AUTOSAR XML (schema 4-2-1)
standard types defined: boolean, float32, uint8, boolean_CompuMethod, boolean_DataConstr, float32_DataConstr, uint8_DataConstr
package /ComponentTypes
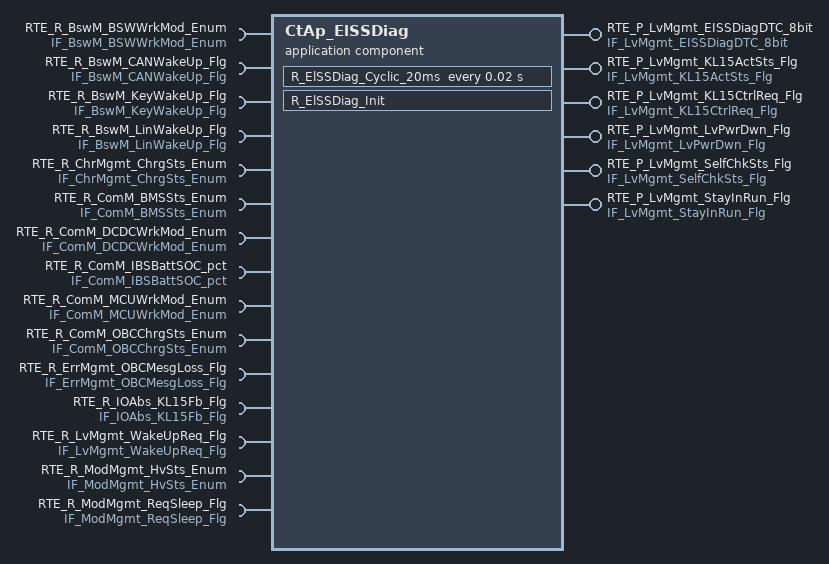
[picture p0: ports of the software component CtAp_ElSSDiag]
  application sw component type CtAp_ElSSDiag
    6 x provide port:
      RTE_P_LvMgmt_EISSDiagDTC_8bit: nonqueued-sender-com-spec{data-element=tec_LvMgmt_EISSDiagDTC_8bit, init-value=0}, provided-interface=IF_LvMgmt_EISSDiagDTC_8bit
      RTE_P_LvMgmt_KL15ActSts_Flg: nonqueued-sender-com-spec{data-element=tec_LvMgmt_KL15ActSts_Flg, init-value=0}, provided-interface=IF_LvMgmt_KL15ActSts_Flg
      RTE_P_LvMgmt_KL15CtrlReq_Flg: nonqueued-sender-com-spec{data-element=tec_LvMgmt_KL15CtrlReq_Flg, init-value=0}, provided-interface=IF_LvMgmt_KL15CtrlReq_Flg
      RTE_P_LvMgmt_LvPwrDwn_Flg: nonqueued-sender-com-spec{data-element=tec_LvMgmt_LvPwrDwn_Flg, init-value=0}, provided-interface=IF_LvMgmt_LvPwrDwn_Flg
      RTE_P_LvMgmt_SelfChkSts_Flg: nonqueued-sender-com-spec{data-element=tec_LvMgmt_SelfChkSts_Flg, init-value=0}, provided-interface=IF_LvMgmt_SelfChkSts_Flg
      RTE_P_LvMgmt_StayInRun_Flg: nonqueued-sender-com-spec{data-element=tec_LvMgmt_StayInRun_Flg, init-value=0}, provided-interface=IF_LvMgmt_StayInRun_Flg
    15 x require port:
      RTE_R_BswM_BSWWrkMod_Enum: nonqueued-receiver-com-spec{data-element=tec_BswM_BSWWrkMod_Enum, filter=data-filter-type=ALWAYS, init-value=0}, required-interface=IF_BswM_BSWWrkMod_Enum
      RTE_R_BswM_CANWakeUp_Flg: nonqueued-receiver-com-spec{data-element=tec_BswM_CANWakeUp_Flg, filter=data-filter-type=ALWAYS, init-value=0}, required-interface=IF_BswM_CANWakeUp_Flg
      RTE_R_BswM_KeyWakeUp_Flg: nonqueued-receiver-com-spec{data-element=tec_BswM_KeyWakeUp_Flg, filter=data-filter-type=ALWAYS, init-value=0}, required-interface=IF_BswM_KeyWakeUp_Flg
      RTE_R_BswM_LinWakeUp_Flg: nonqueued-receiver-com-spec{data-element=tec_BswM_LinWakeUp_Flg, filter=data-filter-type=ALWAYS, init-value=0}, required-interface=IF_BswM_LinWakeUp_Flg
      RTE_R_ChrMgmt_ChrgSts_Enum: nonqueued-receiver-com-spec{data-element=tec_ChrMgmt_ChrgSts_Enum, filter=data-filter-type=ALWAYS, init-value=0}, required-interface=IF_ChrMgmt_ChrgSts_Enum
      RTE_R_ComM_BMSSts_Enum: nonqueued-receiver-com-spec{data-element=tec_ComM_BMSSts_Enum, filter=data-filter-type=ALWAYS, init-value=0}, required-interface=IF_ComM_BMSSts_Enum
      RTE_R_ComM_DCDCWrkMod_Enum: nonqueued-receiver-com-spec{data-element=tec_ComM_DCDCWrkMod_Enum, filter=data-filter-type=ALWAYS, init-value=0}, required-interface=IF_ComM_DCDCWrkMod_Enum
      RTE_R_ComM_IBSBattSOC_pct: nonqueued-receiver-com-spec{data-element=tec_ComM_IBSBattSOC_pct, filter=data-filter-type=ALWAYS, init-value=0}, required-interface=IF_ComM_IBSBattSOC_pct
      RTE_R_ComM_MCUWrkMod_Enum: nonqueued-receiver-com-spec{data-element=tec_ComM_MCUWrkMod_Enum, filter=data-filter-type=ALWAYS, init-value=0}, required-interface=IF_ComM_MCUWrkMod_Enum
      RTE_R_ComM_OBCChrgSts_Enum: nonqueued-receiver-com-spec{data-element=tec_ComM_OBCChrgSts_Enum, filter=data-filter-type=ALWAYS, init-value=0}, required-interface=IF_ComM_OBCChrgSts_Enum
      RTE_R_ErrMgmt_OBCMesgLoss_Flg: nonqueued-receiver-com-spec{data-element=tec_ErrMgmt_OBCMesgLoss_Flg, filter=data-filter-type=ALWAYS, init-value=0}, required-interface=IF_ErrMgmt_OBCMesgLoss_Flg
      RTE_R_IOAbs_KL15Fb_Flg: nonqueued-receiver-com-spec{data-element=tec_IOAbs_KL15Fb_Flg, filter=data-filter-type=ALWAYS, init-value=0}, required-interface=IF_IOAbs_KL15Fb_Flg
      RTE_R_LvMgmt_WakeUpReq_Flg: nonqueued-receiver-com-spec{data-element=tec_LvMgmt_WakeUpReq_Flg, filter=data-filter-type=ALWAYS, init-value=0}, required-interface=IF_LvMgmt_WakeUpReq_Flg
      RTE_R_ModMgmt_HvSts_Enum: nonqueued-receiver-com-spec{data-element=tec_ModMgmt_HvSts_Enum, filter=data-filter-type=ALWAYS, init-value=0}, required-interface=IF_ModMgmt_HvSts_Enum
      RTE_R_ModMgmt_ReqSleep_Flg: nonqueued-receiver-com-spec{data-element=tec_ModMgmt_ReqSleep_Flg, filter=data-filter-type=ALWAYS, init-value=0}, required-interface=IF_ModMgmt_ReqSleep_Flg
    behavior CtAp_ElSSDiag_InternalBehavior
      timing event TMT_R_ElSSDiag_Cyclic_20ms: start-on-event=R_ElSSDiag_Cyclic_20ms, period=0.02
      init event CtAp_ElSSDiag_InitEvent: start-on-event=R_ElSSDiag_Init
      runnable R_ElSSDiag_Cyclic_20ms
        data-receive-point-by-arguments:
          15 x access:
            REC_RTE_R_BswM_BSWWrkMod_Enum_tec_BswM_BSWWrkMod_Enum: accessed-variable=RTE_R_BswM_BSWWrkMod_Enum.tec_BswM_BSWWrkMod_Enum
            REC_RTE_R_BswM_CANWakeUp_Flg_tec_BswM_CANWakeUp_Flg: accessed-variable=RTE_R_BswM_CANWakeUp_Flg.tec_BswM_CANWakeUp_Flg
            REC_RTE_R_BswM_KeyWakeUp_Flg_tec_BswM_KeyWakeUp_Flg: accessed-variable=RTE_R_BswM_KeyWakeUp_Flg.tec_BswM_KeyWakeUp_Flg
            REC_RTE_R_BswM_LinWakeUp_Flg_tec_BswM_LinWakeUp_Flg: accessed-variable=RTE_R_BswM_LinWakeUp_Flg.tec_BswM_LinWakeUp_Flg
            REC_RTE_R_ChrMgmt_ChrgSts_Enum_tec_ChrMgmt_ChrgSts_Enum: accessed-variable=RTE_R_ChrMgmt_ChrgSts_Enum.tec_ChrMgmt_ChrgSts_Enum
            REC_RTE_R_ComM_BMSSts_Enum_tec_ComM_BMSSts_Enum: accessed-variable=RTE_R_ComM_BMSSts_Enum.tec_ComM_BMSSts_Enum
            REC_RTE_R_ComM_DCDCWrkMod_Enum_tec_ComM_DCDCWrkMod_Enum: accessed-variable=RTE_R_ComM_DCDCWrkMod_Enum.tec_ComM_DCDCWrkMod_Enum
            REC_RTE_R_ComM_IBSBattSOC_pct_tec_ComM_IBSBattSOC_pct: accessed-variable=RTE_R_ComM_IBSBattSOC_pct.tec_ComM_IBSBattSOC_pct
            REC_RTE_R_ComM_MCUWrkMod_Enum_tec_ComM_MCUWrkMod_Enum: accessed-variable=RTE_R_ComM_MCUWrkMod_Enum.tec_ComM_MCUWrkMod_Enum
            REC_RTE_R_ComM_OBCChrgSts_Enum_tec_ComM_OBCChrgSts_Enum: accessed-variable=RTE_R_ComM_OBCChrgSts_Enum.tec_ComM_OBCChrgSts_Enum
            REC_RTE_R_ErrMgmt_OBCMesgLoss_Flg_tec_ErrMgmt_OBCMesgLoss_Flg: accessed-variable=RTE_R_ErrMgmt_OBCMesgLoss_Flg.tec_ErrMgmt_OBCMesgLoss_Flg
            REC_RTE_R_IOAbs_KL15Fb_Flg_tec_IOAbs_KL15Fb_Flg: accessed-variable=RTE_R_IOAbs_KL15Fb_Flg.tec_IOAbs_KL15Fb_Flg
            REC_RTE_R_LvMgmt_WakeUpReq_Flg_tec_LvMgmt_WakeUpReq_Flg: accessed-variable=RTE_R_LvMgmt_WakeUpReq_Flg.tec_LvMgmt_WakeUpReq_Flg
            REC_RTE_R_ModMgmt_HvSts_Enum_tec_ModMgmt_HvSts_Enum: accessed-variable=RTE_R_ModMgmt_HvSts_Enum.tec_ModMgmt_HvSts_Enum
            REC_RTE_R_ModMgmt_ReqSleep_Flg_tec_ModMgmt_ReqSleep_Flg: accessed-variable=RTE_R_ModMgmt_ReqSleep_Flg.tec_ModMgmt_ReqSleep_Flg
        data-send-points:
          6 x access:
            SEND_RTE_P_LvMgmt_EISSDiagDTC_8bit_tec_LvMgmt_EISSDiagDTC_8bit: accessed-variable=RTE_P_LvMgmt_EISSDiagDTC_8bit.tec_LvMgmt_EISSDiagDTC_8bit
            SEND_RTE_P_LvMgmt_KL15ActSts_Flg_tec_LvMgmt_KL15ActSts_Flg: accessed-variable=RTE_P_LvMgmt_KL15ActSts_Flg.tec_LvMgmt_KL15ActSts_Flg
            SEND_RTE_P_LvMgmt_KL15CtrlReq_Flg_tec_LvMgmt_KL15CtrlReq_Flg: accessed-variable=RTE_P_LvMgmt_KL15CtrlReq_Flg.tec_LvMgmt_KL15CtrlReq_Flg
            SEND_RTE_P_LvMgmt_LvPwrDwn_Flg_tec_LvMgmt_LvPwrDwn_Flg: accessed-variable=RTE_P_LvMgmt_LvPwrDwn_Flg.tec_LvMgmt_LvPwrDwn_Flg
            SEND_RTE_P_LvMgmt_SelfChkSts_Flg_tec_LvMgmt_SelfChkSts_Flg: accessed-variable=RTE_P_LvMgmt_SelfChkSts_Flg.tec_LvMgmt_SelfChkSts_Flg
            SEND_RTE_P_LvMgmt_StayInRun_Flg_tec_LvMgmt_StayInRun_Flg: accessed-variable=RTE_P_LvMgmt_StayInRun_Flg.tec_LvMgmt_StayInRun_Flg
      runnable R_ElSSDiag_Init
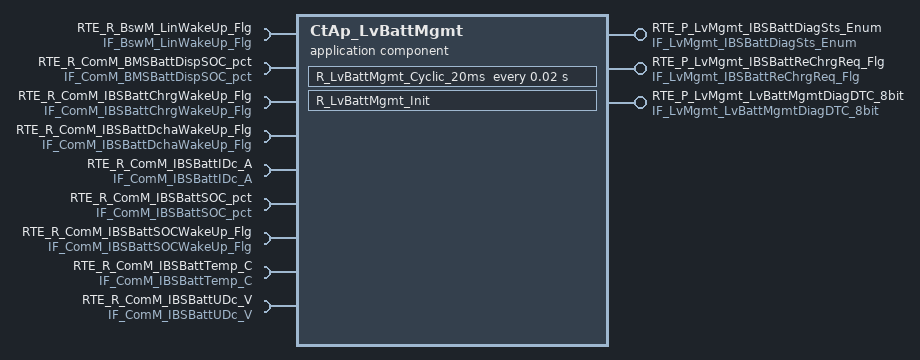
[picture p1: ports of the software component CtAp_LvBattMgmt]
  application sw component type CtAp_LvBattMgmt
    provide port RTE_P_LvMgmt_IBSBattDiagSts_Enum: nonqueued-sender-com-spec{data-element=tec_LvMgmt_IBSBattDiagSts_Enum, init-value=0}, provided-interface=IF_LvMgmt_IBSBattDiagSts_Enum
    provide port RTE_P_LvMgmt_IBSBattReChrgReq_Flg: nonqueued-sender-com-spec{data-element=tec_LvMgmt_IBSBattReChrgReq_Flg, init-value=0}, provided-interface=IF_LvMgmt_IBSBattReChrgReq_Flg
    provide port RTE_P_LvMgmt_LvBattMgmtDiagDTC_8bit: nonqueued-sender-com-spec{data-element=tec_LvMgmt_LvBattMgmtDiagDTC_8bit, init-value=0}, provided-interface=IF_LvMgmt_LvBattMgmtDiagDTC_8bit
    9 x require port:
      RTE_R_BswM_LinWakeUp_Flg: nonqueued-receiver-com-spec{data-element=tec_BswM_LinWakeUp_Flg, filter=data-filter-type=ALWAYS, init-value=0}, required-interface=IF_BswM_LinWakeUp_Flg
      RTE_R_ComM_BMSBattDispSOC_pct: nonqueued-receiver-com-spec{data-element=tec_ComM_BMSBattDispSOC_pct, filter=data-filter-type=ALWAYS, init-value=0}, required-interface=IF_ComM_BMSBattDispSOC_pct
      RTE_R_ComM_IBSBattChrgWakeUp_Flg: nonqueued-receiver-com-spec{data-element=tec_ComM_IBSBattChrgWakeUp_Flg, filter=data-filter-type=ALWAYS, init-value=0}, required-interface=IF_ComM_IBSBattChrgWakeUp_Flg
      RTE_R_ComM_IBSBattDchaWakeUp_Flg: nonqueued-receiver-com-spec{data-element=tec_ComM_IBSBattDchaWakeUp_Flg, filter=data-filter-type=ALWAYS, init-value=0}, required-interface=IF_ComM_IBSBattDchaWakeUp_Flg
      RTE_R_ComM_IBSBattIDc_A: nonqueued-receiver-com-spec{data-element=tec_ComM_IBSBattIDc_A, filter=data-filter-type=ALWAYS, init-value=0}, required-interface=IF_ComM_IBSBattIDc_A
      RTE_R_ComM_IBSBattSOC_pct: nonqueued-receiver-com-spec{data-element=tec_ComM_IBSBattSOC_pct, filter=data-filter-type=ALWAYS, init-value=0}, required-interface=IF_ComM_IBSBattSOC_pct
      RTE_R_ComM_IBSBattSOCWakeUp_Flg: nonqueued-receiver-com-spec{data-element=tec_ComM_IBSBattSOCWakeUp_Flg, filter=data-filter-type=ALWAYS, init-value=0}, required-interface=IF_ComM_IBSBattSOCWakeUp_Flg
      RTE_R_ComM_IBSBattTemp_C: nonqueued-receiver-com-spec{data-element=tec_ComM_IBSBattTemp_C, filter=data-filter-type=ALWAYS, init-value=0}, required-interface=IF_ComM_IBSBattTemp_C
      RTE_R_ComM_IBSBattUDc_V: nonqueued-receiver-com-spec{data-element=tec_ComM_IBSBattUDc_V, filter=data-filter-type=ALWAYS, init-value=0}, required-interface=IF_ComM_IBSBattUDc_V
    behavior CtAp_LvBattMgmt_InternalBehavior
      timing event TMT_R_LvBattMgmt_Cyclic_20ms: start-on-event=R_LvBattMgmt_Cyclic_20ms, period=0.02
      init event CtAp_LvBattMgmt_InitEvent: start-on-event=R_LvBattMgmt_Init
      runnable R_LvBattMgmt_Cyclic_20ms
        data-receive-point-by-arguments:
          9 x access:
            REC_RTE_R_BswM_LinWakeUp_Flg_tec_BswM_LinWakeUp_Flg: accessed-variable=RTE_R_BswM_LinWakeUp_Flg.tec_BswM_LinWakeUp_Flg
            REC_RTE_R_ComM_BMSBattDispSOC_pct_tec_ComM_BMSBattDispSOC_pct: accessed-variable=RTE_R_ComM_BMSBattDispSOC_pct.tec_ComM_BMSBattDispSOC_pct
            REC_RTE_R_ComM_IBSBattChrgWakeUp_Flg_tec_ComM_IBSBattChrgWakeUp_Flg: accessed-variable=RTE_R_ComM_IBSBattChrgWakeUp_Flg.tec_ComM_IBSBattChrgWakeUp_Flg
            REC_RTE_R_ComM_IBSBattDchaWakeUp_Flg_tec_ComM_IBSBattDchaWakeUp_Flg: accessed-variable=RTE_R_ComM_IBSBattDchaWakeUp_Flg.tec_ComM_IBSBattDchaWakeUp_Flg
            REC_RTE_R_ComM_IBSBattIDc_A_tec_ComM_IBSBattIDc_A: accessed-variable=RTE_R_ComM_IBSBattIDc_A.tec_ComM_IBSBattIDc_A
            REC_RTE_R_ComM_IBSBattSOC_pct_tec_ComM_IBSBattSOC_pct: accessed-variable=RTE_R_ComM_IBSBattSOC_pct.tec_ComM_IBSBattSOC_pct
            REC_RTE_R_ComM_IBSBattSOCWakeUp_Flg_tec_ComM_IBSBattSOCWakeUp_Flg: accessed-variable=RTE_R_ComM_IBSBattSOCWakeUp_Flg.tec_ComM_IBSBattSOCWakeUp_Flg
            REC_RTE_R_ComM_IBSBattTemp_C_tec_ComM_IBSBattTemp_C: accessed-variable=RTE_R_ComM_IBSBattTemp_C.tec_ComM_IBSBattTemp_C
            REC_RTE_R_ComM_IBSBattUDc_V_tec_ComM_IBSBattUDc_V: accessed-variable=RTE_R_ComM_IBSBattUDc_V.tec_ComM_IBSBattUDc_V
        data-send-points:
          access SEND_RTE_P_LvMgmt_IBSBattDiagSts_Enum_tec_LvMgmt_IBSBattDiagSts_Enum: accessed-variable=RTE_P_LvMgmt_IBSBattDiagSts_Enum.tec_LvMgmt_IBSBattDiagSts_Enum
          access SEND_RTE_P_LvMgmt_IBSBattReChrgReq_Flg_tec_LvMgmt_IBSBattReChrgReq_Flg: accessed-variable=RTE_P_LvMgmt_IBSBattReChrgReq_Flg.tec_LvMgmt_IBSBattReChrgReq_Flg
          access SEND_RTE_P_LvMgmt_LvBattMgmtDiagDTC_8bit_tec_LvMgmt_LvBattMgmtDiagDTC_8bit: accessed-variable=RTE_P_LvMgmt_LvBattMgmtDiagDTC_8bit.tec_LvMgmt_LvBattMgmtDiagDTC_8bit
      runnable R_LvBattMgmt_Init
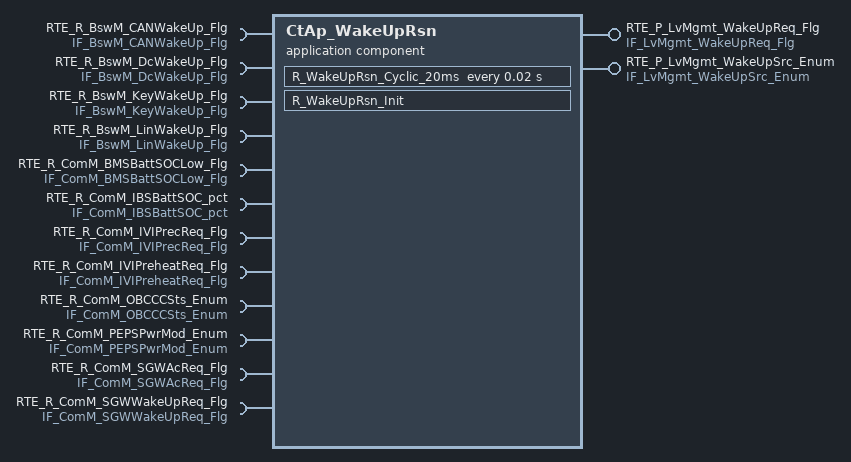
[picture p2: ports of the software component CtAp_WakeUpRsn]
  application sw component type CtAp_WakeUpRsn
    provide port RTE_P_LvMgmt_WakeUpReq_Flg: nonqueued-sender-com-spec{data-element=tec_LvMgmt_WakeUpReq_Flg, init-value=0}, provided-interface=IF_LvMgmt_WakeUpReq_Flg
    provide port RTE_P_LvMgmt_WakeUpSrc_Enum: nonqueued-sender-com-spec{data-element=tec_LvMgmt_WakeUpSrc_Enum, init-value=0}, provided-interface=IF_LvMgmt_WakeUpSrc_Enum
    12 x require port:
      RTE_R_BswM_CANWakeUp_Flg: nonqueued-receiver-com-spec{data-element=tec_BswM_CANWakeUp_Flg, filter=data-filter-type=ALWAYS, init-value=0}, required-interface=IF_BswM_CANWakeUp_Flg
      RTE_R_BswM_DcWakeUp_Flg: nonqueued-receiver-com-spec{data-element=tec_BswM_DcWakeUp_Flg, filter=data-filter-type=ALWAYS, init-value=0}, required-interface=IF_BswM_DcWakeUp_Flg
      RTE_R_BswM_KeyWakeUp_Flg: nonqueued-receiver-com-spec{data-element=tec_BswM_KeyWakeUp_Flg, filter=data-filter-type=ALWAYS, init-value=0}, required-interface=IF_BswM_KeyWakeUp_Flg
      RTE_R_BswM_LinWakeUp_Flg: nonqueued-receiver-com-spec{data-element=tec_BswM_LinWakeUp_Flg, filter=data-filter-type=ALWAYS, init-value=0}, required-interface=IF_BswM_LinWakeUp_Flg
      RTE_R_ComM_BMSBattSOCLow_Flg: nonqueued-receiver-com-spec{data-element=tec_ComM_BMSBattSOCLow_Flg, filter=data-filter-type=ALWAYS, init-value=0}, required-interface=IF_ComM_BMSBattSOCLow_Flg
      RTE_R_ComM_IBSBattSOC_pct: nonqueued-receiver-com-spec{data-element=tec_ComM_IBSBattSOC_pct, filter=data-filter-type=ALWAYS, init-value=0}, required-interface=IF_ComM_IBSBattSOC_pct
      RTE_R_ComM_IVIPrecReq_Flg: nonqueued-receiver-com-spec{data-element=tec_ComM_IVIPrecReq_Flg, filter=data-filter-type=ALWAYS, init-value=0}, required-interface=IF_ComM_IVIPrecReq_Flg
      RTE_R_ComM_IVIPreheatReq_Flg: nonqueued-receiver-com-spec{data-element=tec_ComM_IVIPreheatReq_Flg, filter=data-filter-type=ALWAYS, init-value=0}, required-interface=IF_ComM_IVIPreheatReq_Flg
      RTE_R_ComM_OBCCCSts_Enum: nonqueued-receiver-com-spec{data-element=tec_ComM_OBCCCSts_Enum, filter=data-filter-type=ALWAYS, init-value=0}, required-interface=IF_ComM_OBCCCSts_Enum
      RTE_R_ComM_PEPSPwrMod_Enum: nonqueued-receiver-com-spec{data-element=tec_ComM_PEPSPwrMod_Enum, filter=data-filter-type=ALWAYS, init-value=0}, required-interface=IF_ComM_PEPSPwrMod_Enum
      RTE_R_ComM_SGWAcReq_Flg: nonqueued-receiver-com-spec{data-element=tec_ComM_SGWAcReq_Flg, filter=data-filter-type=ALWAYS, init-value=0}, required-interface=IF_ComM_SGWAcReq_Flg
      RTE_R_ComM_SGWWakeUpReq_Flg: nonqueued-receiver-com-spec{data-element=tec_ComM_SGWWakeUpReq_Flg, filter=data-filter-type=ALWAYS, init-value=0}, required-interface=IF_ComM_SGWWakeUpReq_Flg
    behavior CtAp_WakeUpRsn_InternalBehavior
      timing event TMT_R_WakeUpRsn_Cyclic_20ms: start-on-event=R_WakeUpRsn_Cyclic_20ms, period=0.02
      init event CtAp_WakeUpRsn_InitEvent: start-on-event=R_WakeUpRsn_Init
      runnable R_WakeUpRsn_Cyclic_20ms
        data-receive-point-by-arguments:
          12 x access:
            REC_RTE_R_BswM_CANWakeUp_Flg_tec_BswM_CANWakeUp_Flg: accessed-variable=RTE_R_BswM_CANWakeUp_Flg.tec_BswM_CANWakeUp_Flg
            REC_RTE_R_BswM_DcWakeUp_Flg_tec_BswM_DcWakeUp_Flg: accessed-variable=RTE_R_BswM_DcWakeUp_Flg.tec_BswM_DcWakeUp_Flg
            REC_RTE_R_BswM_KeyWakeUp_Flg_tec_BswM_KeyWakeUp_Flg: accessed-variable=RTE_R_BswM_KeyWakeUp_Flg.tec_BswM_KeyWakeUp_Flg
            REC_RTE_R_BswM_LinWakeUp_Flg_tec_BswM_LinWakeUp_Flg: accessed-variable=RTE_R_BswM_LinWakeUp_Flg.tec_BswM_LinWakeUp_Flg
            REC_RTE_R_ComM_BMSBattSOCLow_Flg_tec_ComM_BMSBattSOCLow_Flg: accessed-variable=RTE_R_ComM_BMSBattSOCLow_Flg.tec_ComM_BMSBattSOCLow_Flg
            REC_RTE_R_ComM_IBSBattSOC_pct_tec_ComM_IBSBattSOC_pct: accessed-variable=RTE_R_ComM_IBSBattSOC_pct.tec_ComM_IBSBattSOC_pct
            REC_RTE_R_ComM_IVIPrecReq_Flg_tec_ComM_IVIPrecReq_Flg: accessed-variable=RTE_R_ComM_IVIPrecReq_Flg.tec_ComM_IVIPrecReq_Flg
            REC_RTE_R_ComM_IVIPreheatReq_Flg_tec_ComM_IVIPreheatReq_Flg: accessed-variable=RTE_R_ComM_IVIPreheatReq_Flg.tec_ComM_IVIPreheatReq_Flg
            REC_RTE_R_ComM_OBCCCSts_Enum_tec_ComM_OBCCCSts_Enum: accessed-variable=RTE_R_ComM_OBCCCSts_Enum.tec_ComM_OBCCCSts_Enum
            REC_RTE_R_ComM_PEPSPwrMod_Enum_tec_ComM_PEPSPwrMod_Enum: accessed-variable=RTE_R_ComM_PEPSPwrMod_Enum.tec_ComM_PEPSPwrMod_Enum
            REC_RTE_R_ComM_SGWAcReq_Flg_tec_ComM_SGWAcReq_Flg: accessed-variable=RTE_R_ComM_SGWAcReq_Flg.tec_ComM_SGWAcReq_Flg
            REC_RTE_R_ComM_SGWWakeUpReq_Flg_tec_ComM_SGWWakeUpReq_Flg: accessed-variable=RTE_R_ComM_SGWWakeUpReq_Flg.tec_ComM_SGWWakeUpReq_Flg
        data-send-points:
          access SEND_RTE_P_LvMgmt_WakeUpReq_Flg_tec_LvMgmt_WakeUpReq_Flg: accessed-variable=RTE_P_LvMgmt_WakeUpReq_Flg.tec_LvMgmt_WakeUpReq_Flg
          access SEND_RTE_P_LvMgmt_WakeUpSrc_Enum_tec_LvMgmt_WakeUpSrc_Enum: accessed-variable=RTE_P_LvMgmt_WakeUpSrc_Enum.tec_LvMgmt_WakeUpSrc_Enum
      runnable R_WakeUpRsn_Init
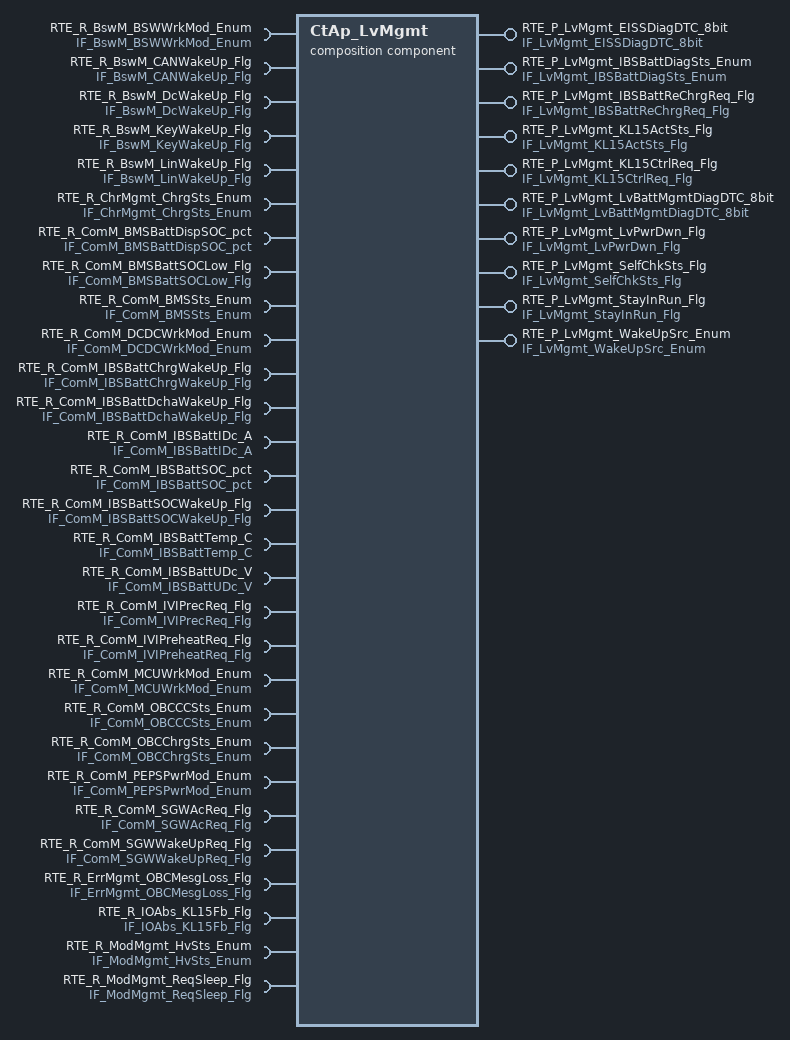
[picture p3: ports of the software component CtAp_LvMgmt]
  composition sw component type CtAp_LvMgmt
    10 x provide port:
      RTE_P_LvMgmt_EISSDiagDTC_8bit: nonqueued-sender-com-spec{data-element=tec_LvMgmt_EISSDiagDTC_8bit, init-value=0}, provided-interface=IF_LvMgmt_EISSDiagDTC_8bit
      RTE_P_LvMgmt_IBSBattDiagSts_Enum: nonqueued-sender-com-spec{data-element=tec_LvMgmt_IBSBattDiagSts_Enum, init-value=0}, provided-interface=IF_LvMgmt_IBSBattDiagSts_Enum
      RTE_P_LvMgmt_IBSBattReChrgReq_Flg: nonqueued-sender-com-spec{data-element=tec_LvMgmt_IBSBattReChrgReq_Flg, init-value=0}, provided-interface=IF_LvMgmt_IBSBattReChrgReq_Flg
      RTE_P_LvMgmt_KL15ActSts_Flg: nonqueued-sender-com-spec{data-element=tec_LvMgmt_KL15ActSts_Flg, init-value=0}, provided-interface=IF_LvMgmt_KL15ActSts_Flg
      RTE_P_LvMgmt_KL15CtrlReq_Flg: nonqueued-sender-com-spec{data-element=tec_LvMgmt_KL15CtrlReq_Flg, init-value=0}, provided-interface=IF_LvMgmt_KL15CtrlReq_Flg
      RTE_P_LvMgmt_LvBattMgmtDiagDTC_8bit: nonqueued-sender-com-spec{data-element=tec_LvMgmt_LvBattMgmtDiagDTC_8bit, init-value=0}, provided-interface=IF_LvMgmt_LvBattMgmtDiagDTC_8bit
      RTE_P_LvMgmt_LvPwrDwn_Flg: nonqueued-sender-com-spec{data-element=tec_LvMgmt_LvPwrDwn_Flg, init-value=0}, provided-interface=IF_LvMgmt_LvPwrDwn_Flg
      RTE_P_LvMgmt_SelfChkSts_Flg: nonqueued-sender-com-spec{data-element=tec_LvMgmt_SelfChkSts_Flg, init-value=0}, provided-interface=IF_LvMgmt_SelfChkSts_Flg
      RTE_P_LvMgmt_StayInRun_Flg: nonqueued-sender-com-spec{data-element=tec_LvMgmt_StayInRun_Flg, init-value=0}, provided-interface=IF_LvMgmt_StayInRun_Flg
      RTE_P_LvMgmt_WakeUpSrc_Enum: nonqueued-sender-com-spec{data-element=tec_LvMgmt_WakeUpSrc_Enum, init-value=0}, provided-interface=IF_LvMgmt_WakeUpSrc_Enum
    29 x require port:
      RTE_R_BswM_BSWWrkMod_Enum: nonqueued-receiver-com-spec{data-element=tec_BswM_BSWWrkMod_Enum, filter=data-filter-type=ALWAYS, init-value=0}, required-interface=IF_BswM_BSWWrkMod_Enum
      RTE_R_BswM_CANWakeUp_Flg: nonqueued-receiver-com-spec{data-element=tec_BswM_CANWakeUp_Flg, filter=data-filter-type=ALWAYS, init-value=0}, required-interface=IF_BswM_CANWakeUp_Flg
      RTE_R_BswM_DcWakeUp_Flg: nonqueued-receiver-com-spec{data-element=tec_BswM_DcWakeUp_Flg, filter=data-filter-type=ALWAYS, init-value=0}, required-interface=IF_BswM_DcWakeUp_Flg
      RTE_R_BswM_KeyWakeUp_Flg: nonqueued-receiver-com-spec{data-element=tec_BswM_KeyWakeUp_Flg, filter=data-filter-type=ALWAYS, init-value=0}, required-interface=IF_BswM_KeyWakeUp_Flg
      RTE_R_BswM_LinWakeUp_Flg: nonqueued-receiver-com-spec{data-element=tec_BswM_LinWakeUp_Flg, filter=data-filter-type=ALWAYS, init-value=0}, required-interface=IF_BswM_LinWakeUp_Flg
      RTE_R_ChrMgmt_ChrgSts_Enum: nonqueued-receiver-com-spec{data-element=tec_ChrMgmt_ChrgSts_Enum, filter=data-filter-type=ALWAYS, init-value=0}, required-interface=IF_ChrMgmt_ChrgSts_Enum
      RTE_R_ComM_BMSBattDispSOC_pct: nonqueued-receiver-com-spec{data-element=tec_ComM_BMSBattDispSOC_pct, filter=data-filter-type=ALWAYS, init-value=0}, required-interface=IF_ComM_BMSBattDispSOC_pct
      RTE_R_ComM_BMSBattSOCLow_Flg: nonqueued-receiver-com-spec{data-element=tec_ComM_BMSBattSOCLow_Flg, filter=data-filter-type=ALWAYS, init-value=0}, required-interface=IF_ComM_BMSBattSOCLow_Flg
      RTE_R_ComM_BMSSts_Enum: nonqueued-receiver-com-spec{data-element=tec_ComM_BMSSts_Enum, filter=data-filter-type=ALWAYS, init-value=0}, required-interface=IF_ComM_BMSSts_Enum
      RTE_R_ComM_DCDCWrkMod_Enum: nonqueued-receiver-com-spec{data-element=tec_ComM_DCDCWrkMod_Enum, filter=data-filter-type=ALWAYS, init-value=0}, required-interface=IF_ComM_DCDCWrkMod_Enum
      RTE_R_ComM_IBSBattChrgWakeUp_Flg: nonqueued-receiver-com-spec{data-element=tec_ComM_IBSBattChrgWakeUp_Flg, filter=data-filter-type=ALWAYS, init-value=0}, required-interface=IF_ComM_IBSBattChrgWakeUp_Flg
      RTE_R_ComM_IBSBattDchaWakeUp_Flg: nonqueued-receiver-com-spec{data-element=tec_ComM_IBSBattDchaWakeUp_Flg, filter=data-filter-type=ALWAYS, init-value=0}, required-interface=IF_ComM_IBSBattDchaWakeUp_Flg
      RTE_R_ComM_IBSBattIDc_A: nonqueued-receiver-com-spec{data-element=tec_ComM_IBSBattIDc_A, filter=data-filter-type=ALWAYS, init-value=0}, required-interface=IF_ComM_IBSBattIDc_A
      RTE_R_ComM_IBSBattSOC_pct: nonqueued-receiver-com-spec{data-element=tec_ComM_IBSBattSOC_pct, filter=data-filter-type=ALWAYS, init-value=0}, required-interface=IF_ComM_IBSBattSOC_pct
      RTE_R_ComM_IBSBattSOCWakeUp_Flg: nonqueued-receiver-com-spec{data-element=tec_ComM_IBSBattSOCWakeUp_Flg, filter=data-filter-type=ALWAYS, init-value=0}, required-interface=IF_ComM_IBSBattSOCWakeUp_Flg
      RTE_R_ComM_IBSBattTemp_C: nonqueued-receiver-com-spec{data-element=tec_ComM_IBSBattTemp_C, filter=data-filter-type=ALWAYS, init-value=0}, required-interface=IF_ComM_IBSBattTemp_C
      RTE_R_ComM_IBSBattUDc_V: nonqueued-receiver-com-spec{data-element=tec_ComM_IBSBattUDc_V, filter=data-filter-type=ALWAYS, init-value=0}, required-interface=IF_ComM_IBSBattUDc_V
      RTE_R_ComM_IVIPrecReq_Flg: nonqueued-receiver-com-spec{data-element=tec_ComM_IVIPrecReq_Flg, filter=data-filter-type=ALWAYS, init-value=0}, required-interface=IF_ComM_IVIPrecReq_Flg
      RTE_R_ComM_IVIPreheatReq_Flg: nonqueued-receiver-com-spec{data-element=tec_ComM_IVIPreheatReq_Flg, filter=data-filter-type=ALWAYS, init-value=0}, required-interface=IF_ComM_IVIPreheatReq_Flg
      RTE_R_ComM_MCUWrkMod_Enum: nonqueued-receiver-com-spec{data-element=tec_ComM_MCUWrkMod_Enum, filter=data-filter-type=ALWAYS, init-value=0}, required-interface=IF_ComM_MCUWrkMod_Enum
      RTE_R_ComM_OBCCCSts_Enum: nonqueued-receiver-com-spec{data-element=tec_ComM_OBCCCSts_Enum, filter=data-filter-type=ALWAYS, init-value=0}, required-interface=IF_ComM_OBCCCSts_Enum
      RTE_R_ComM_OBCChrgSts_Enum: nonqueued-receiver-com-spec{data-element=tec_ComM_OBCChrgSts_Enum, filter=data-filter-type=ALWAYS, init-value=0}, required-interface=IF_ComM_OBCChrgSts_Enum
      RTE_R_ComM_PEPSPwrMod_Enum: nonqueued-receiver-com-spec{data-element=tec_ComM_PEPSPwrMod_Enum, filter=data-filter-type=ALWAYS, init-value=0}, required-interface=IF_ComM_PEPSPwrMod_Enum
      RTE_R_ComM_SGWAcReq_Flg: nonqueued-receiver-com-spec{data-element=tec_ComM_SGWAcReq_Flg, filter=data-filter-type=ALWAYS, init-value=0}, required-interface=IF_ComM_SGWAcReq_Flg
      RTE_R_ComM_SGWWakeUpReq_Flg: nonqueued-receiver-com-spec{data-element=tec_ComM_SGWWakeUpReq_Flg, filter=data-filter-type=ALWAYS, init-value=0}, required-interface=IF_ComM_SGWWakeUpReq_Flg
      RTE_R_ErrMgmt_OBCMesgLoss_Flg: nonqueued-receiver-com-spec{data-element=tec_ErrMgmt_OBCMesgLoss_Flg, filter=data-filter-type=ALWAYS, init-value=0}, required-interface=IF_ErrMgmt_OBCMesgLoss_Flg
      RTE_R_IOAbs_KL15Fb_Flg: nonqueued-receiver-com-spec{data-element=tec_IOAbs_KL15Fb_Flg, filter=data-filter-type=ALWAYS, init-value=0}, required-interface=IF_IOAbs_KL15Fb_Flg
      RTE_R_ModMgmt_HvSts_Enum: nonqueued-receiver-com-spec{data-element=tec_ModMgmt_HvSts_Enum, filter=data-filter-type=ALWAYS, init-value=0}, required-interface=IF_ModMgmt_HvSts_Enum
      RTE_R_ModMgmt_ReqSleep_Flg: nonqueued-receiver-com-spec{data-element=tec_ModMgmt_ReqSleep_Flg, filter=data-filter-type=ALWAYS, init-value=0}, required-interface=IF_ModMgmt_ReqSleep_Flg
    component CtAp_ElSSDiag: type=CtAp_ElSSDiag
    component CtAp_LvBattMgmt: type=CtAp_LvBattMgmt
    component CtAp_WakeUpRsn: type=CtAp_WakeUpRsn
    connect CtAp_WakeUpRsn.RTE_P_LvMgmt_WakeUpReq_Flg -> CtAp_ElSSDiag.RTE_R_LvMgmt_WakeUpReq_Flg
    delegate CtAp_ElSSDiag.RTE_P_LvMgmt_EISSDiagDTC_8bit <-> outer port CtAp_LvMgmt/RTE_P_LvMgmt_EISSDiagDTC_8bit
    delegate CtAp_LvBattMgmt.RTE_P_LvMgmt_IBSBattDiagSts_Enum <-> outer port CtAp_LvMgmt/RTE_P_LvMgmt_IBSBattDiagSts_Enum
    delegate CtAp_LvBattMgmt.RTE_P_LvMgmt_IBSBattReChrgReq_Flg <-> outer port CtAp_LvMgmt/RTE_P_LvMgmt_IBSBattReChrgReq_Flg
    delegate CtAp_ElSSDiag.RTE_P_LvMgmt_KL15ActSts_Flg <-> outer port CtAp_LvMgmt/RTE_P_LvMgmt_KL15ActSts_Flg
    delegate CtAp_ElSSDiag.RTE_P_LvMgmt_KL15CtrlReq_Flg <-> outer port CtAp_LvMgmt/RTE_P_LvMgmt_KL15CtrlReq_Flg
    delegate CtAp_LvBattMgmt.RTE_P_LvMgmt_LvBattMgmtDiagDTC_8bit <-> outer port CtAp_LvMgmt/RTE_P_LvMgmt_LvBattMgmtDiagDTC_8bit
    delegate CtAp_ElSSDiag.RTE_P_LvMgmt_LvPwrDwn_Flg <-> outer port CtAp_LvMgmt/RTE_P_LvMgmt_LvPwrDwn_Flg
    delegate CtAp_ElSSDiag.RTE_P_LvMgmt_SelfChkSts_Flg <-> outer port CtAp_LvMgmt/RTE_P_LvMgmt_SelfChkSts_Flg
    delegate CtAp_ElSSDiag.RTE_P_LvMgmt_StayInRun_Flg <-> outer port CtAp_LvMgmt/RTE_P_LvMgmt_StayInRun_Flg
    delegate CtAp_WakeUpRsn.RTE_P_LvMgmt_WakeUpSrc_Enum <-> outer port CtAp_LvMgmt/RTE_P_LvMgmt_WakeUpSrc_Enum
    delegate CtAp_ElSSDiag.RTE_R_BswM_BSWWrkMod_Enum <-> outer port CtAp_LvMgmt/RTE_R_BswM_BSWWrkMod_Enum
    delegate CtAp_ElSSDiag.RTE_R_BswM_CANWakeUp_Flg <-> outer port CtAp_LvMgmt/RTE_R_BswM_CANWakeUp_Flg
    delegate CtAp_WakeUpRsn.RTE_R_BswM_CANWakeUp_Flg <-> outer port CtAp_LvMgmt/RTE_R_BswM_CANWakeUp_Flg
    delegate CtAp_WakeUpRsn.RTE_R_BswM_DcWakeUp_Flg <-> outer port CtAp_LvMgmt/RTE_R_BswM_DcWakeUp_Flg
    delegate CtAp_ElSSDiag.RTE_R_BswM_KeyWakeUp_Flg <-> outer port CtAp_LvMgmt/RTE_R_BswM_KeyWakeUp_Flg
    delegate CtAp_WakeUpRsn.RTE_R_BswM_KeyWakeUp_Flg <-> outer port CtAp_LvMgmt/RTE_R_BswM_KeyWakeUp_Flg
    delegate CtAp_ElSSDiag.RTE_R_BswM_LinWakeUp_Flg <-> outer port CtAp_LvMgmt/RTE_R_BswM_LinWakeUp_Flg
    delegate CtAp_LvBattMgmt.RTE_R_BswM_LinWakeUp_Flg <-> outer port CtAp_LvMgmt/RTE_R_BswM_LinWakeUp_Flg
    delegate CtAp_WakeUpRsn.RTE_R_BswM_LinWakeUp_Flg <-> outer port CtAp_LvMgmt/RTE_R_BswM_LinWakeUp_Flg
    delegate CtAp_ElSSDiag.RTE_R_ChrMgmt_ChrgSts_Enum <-> outer port CtAp_LvMgmt/RTE_R_ChrMgmt_ChrgSts_Enum
    delegate CtAp_LvBattMgmt.RTE_R_ComM_BMSBattDispSOC_pct <-> outer port CtAp_LvMgmt/RTE_R_ComM_BMSBattDispSOC_pct
    delegate CtAp_WakeUpRsn.RTE_R_ComM_BMSBattSOCLow_Flg <-> outer port CtAp_LvMgmt/RTE_R_ComM_BMSBattSOCLow_Flg
    delegate CtAp_ElSSDiag.RTE_R_ComM_BMSSts_Enum <-> outer port CtAp_LvMgmt/RTE_R_ComM_BMSSts_Enum
    delegate CtAp_ElSSDiag.RTE_R_ComM_DCDCWrkMod_Enum <-> outer port CtAp_LvMgmt/RTE_R_ComM_DCDCWrkMod_Enum
    delegate CtAp_LvBattMgmt.RTE_R_ComM_IBSBattChrgWakeUp_Flg <-> outer port CtAp_LvMgmt/RTE_R_ComM_IBSBattChrgWakeUp_Flg
    delegate CtAp_LvBattMgmt.RTE_R_ComM_IBSBattDchaWakeUp_Flg <-> outer port CtAp_LvMgmt/RTE_R_ComM_IBSBattDchaWakeUp_Flg
    delegate CtAp_LvBattMgmt.RTE_R_ComM_IBSBattIDc_A <-> outer port CtAp_LvMgmt/RTE_R_ComM_IBSBattIDc_A
    delegate CtAp_ElSSDiag.RTE_R_ComM_IBSBattSOC_pct <-> outer port CtAp_LvMgmt/RTE_R_ComM_IBSBattSOC_pct
    delegate CtAp_LvBattMgmt.RTE_R_ComM_IBSBattSOC_pct <-> outer port CtAp_LvMgmt/RTE_R_ComM_IBSBattSOC_pct
    delegate CtAp_WakeUpRsn.RTE_R_ComM_IBSBattSOC_pct <-> outer port CtAp_LvMgmt/RTE_R_ComM_IBSBattSOC_pct
    delegate CtAp_LvBattMgmt.RTE_R_ComM_IBSBattSOCWakeUp_Flg <-> outer port CtAp_LvMgmt/RTE_R_ComM_IBSBattSOCWakeUp_Flg
    delegate CtAp_LvBattMgmt.RTE_R_ComM_IBSBattTemp_C <-> outer port CtAp_LvMgmt/RTE_R_ComM_IBSBattTemp_C
    delegate CtAp_LvBattMgmt.RTE_R_ComM_IBSBattUDc_V <-> outer port CtAp_LvMgmt/RTE_R_ComM_IBSBattUDc_V
    delegate CtAp_WakeUpRsn.RTE_R_ComM_IVIPrecReq_Flg <-> outer port CtAp_LvMgmt/RTE_R_ComM_IVIPrecReq_Flg
    delegate CtAp_WakeUpRsn.RTE_R_ComM_IVIPreheatReq_Flg <-> outer port CtAp_LvMgmt/RTE_R_ComM_IVIPreheatReq_Flg
    delegate CtAp_ElSSDiag.RTE_R_ComM_MCUWrkMod_Enum <-> outer port CtAp_LvMgmt/RTE_R_ComM_MCUWrkMod_Enum
    delegate CtAp_WakeUpRsn.RTE_R_ComM_OBCCCSts_Enum <-> outer port CtAp_LvMgmt/RTE_R_ComM_OBCCCSts_Enum
    delegate CtAp_ElSSDiag.RTE_R_ComM_OBCChrgSts_Enum <-> outer port CtAp_LvMgmt/RTE_R_ComM_OBCChrgSts_Enum
    delegate CtAp_WakeUpRsn.RTE_R_ComM_PEPSPwrMod_Enum <-> outer port CtAp_LvMgmt/RTE_R_ComM_PEPSPwrMod_Enum
    delegate CtAp_WakeUpRsn.RTE_R_ComM_SGWAcReq_Flg <-> outer port CtAp_LvMgmt/RTE_R_ComM_SGWAcReq_Flg
    delegate CtAp_WakeUpRsn.RTE_R_ComM_SGWWakeUpReq_Flg <-> outer port CtAp_LvMgmt/RTE_R_ComM_SGWWakeUpReq_Flg
    delegate CtAp_ElSSDiag.RTE_R_ErrMgmt_OBCMesgLoss_Flg <-> outer port CtAp_LvMgmt/RTE_R_ErrMgmt_OBCMesgLoss_Flg
    delegate CtAp_ElSSDiag.RTE_R_IOAbs_KL15Fb_Flg <-> outer port CtAp_LvMgmt/RTE_R_IOAbs_KL15Fb_Flg
    delegate CtAp_ElSSDiag.RTE_R_ModMgmt_HvSts_Enum <-> outer port CtAp_LvMgmt/RTE_R_ModMgmt_HvSts_Enum
    delegate CtAp_ElSSDiag.RTE_R_ModMgmt_ReqSleep_Flg <-> outer port CtAp_LvMgmt/RTE_R_ModMgmt_ReqSleep_Flg
  swc implementation CtAp_ElSSDiag_Implementation: behavior=CtAp_ElSSDiag_InternalBehavior
    code-descriptors:
      code Default: artifact-descriptors=autosar-engineering-object={short-label=Default, category=SWOBJ}
  swc implementation CtAp_LvBattMgmt_Implementation: behavior=CtAp_LvBattMgmt_InternalBehavior
    code-descriptors:
      code Default: artifact-descriptors=autosar-engineering-object={short-label=Default, category=SWOBJ}
  swc implementation CtAp_WakeUpRsn_Implementation: behavior=CtAp_WakeUpRsn_InternalBehavior
    code-descriptors:
      code Default: artifact-descriptors=autosar-engineering-object={short-label=Default, category=SWOBJ}
package /PortInterfaces
  40 x sender receiver interface:
    IF_BswM_BSWWrkMod_Enum: invalidation-policy{data-element=tec_BswM_BSWWrkMod_Enum, handle-invalid=DONT-INVALIDATE}
      data tec_BswM_BSWWrkMod_Enum: type=uint8
    IF_BswM_CANWakeUp_Flg: invalidation-policy{data-element=tec_BswM_CANWakeUp_Flg, handle-invalid=DONT-INVALIDATE}
      data tec_BswM_CANWakeUp_Flg: type=boolean
    IF_BswM_DcWakeUp_Flg: invalidation-policy{data-element=tec_BswM_DcWakeUp_Flg, handle-invalid=DONT-INVALIDATE}
      data tec_BswM_DcWakeUp_Flg: type=boolean
    IF_BswM_KeyWakeUp_Flg: invalidation-policy{data-element=tec_BswM_KeyWakeUp_Flg, handle-invalid=DONT-INVALIDATE}
      data tec_BswM_KeyWakeUp_Flg: type=boolean
    IF_BswM_LinWakeUp_Flg: invalidation-policy{data-element=tec_BswM_LinWakeUp_Flg, handle-invalid=DONT-INVALIDATE}
      data tec_BswM_LinWakeUp_Flg: type=boolean
    IF_ChrMgmt_ChrgSts_Enum: invalidation-policy{data-element=tec_ChrMgmt_ChrgSts_Enum, handle-invalid=DONT-INVALIDATE}
      data tec_ChrMgmt_ChrgSts_Enum: type=uint8
    IF_ComM_BMSBattDispSOC_pct: invalidation-policy{data-element=tec_ComM_BMSBattDispSOC_pct, handle-invalid=DONT-INVALIDATE}
      data tec_ComM_BMSBattDispSOC_pct: type=float32
    IF_ComM_BMSBattSOCLow_Flg: invalidation-policy{data-element=tec_ComM_BMSBattSOCLow_Flg, handle-invalid=DONT-INVALIDATE}
      data tec_ComM_BMSBattSOCLow_Flg: type=boolean
    IF_ComM_BMSSts_Enum: invalidation-policy{data-element=tec_ComM_BMSSts_Enum, handle-invalid=DONT-INVALIDATE}
      data tec_ComM_BMSSts_Enum: type=uint8
    IF_ComM_DCDCWrkMod_Enum: invalidation-policy{data-element=tec_ComM_DCDCWrkMod_Enum, handle-invalid=DONT-INVALIDATE}
      data tec_ComM_DCDCWrkMod_Enum: type=uint8
    IF_ComM_IBSBattChrgWakeUp_Flg: invalidation-policy{data-element=tec_ComM_IBSBattChrgWakeUp_Flg, handle-invalid=DONT-INVALIDATE}
      data tec_ComM_IBSBattChrgWakeUp_Flg: type=boolean
    IF_ComM_IBSBattDchaWakeUp_Flg: invalidation-policy{data-element=tec_ComM_IBSBattDchaWakeUp_Flg, handle-invalid=DONT-INVALIDATE}
      data tec_ComM_IBSBattDchaWakeUp_Flg: type=boolean
    IF_ComM_IBSBattIDc_A: invalidation-policy{data-element=tec_ComM_IBSBattIDc_A, handle-invalid=DONT-INVALIDATE}
      data tec_ComM_IBSBattIDc_A: type=float32
    IF_ComM_IBSBattSOC_pct: invalidation-policy{data-element=tec_ComM_IBSBattSOC_pct, handle-invalid=DONT-INVALIDATE}
      data tec_ComM_IBSBattSOC_pct: type=float32
    IF_ComM_IBSBattSOCWakeUp_Flg: invalidation-policy{data-element=tec_ComM_IBSBattSOCWakeUp_Flg, handle-invalid=DONT-INVALIDATE}
      data tec_ComM_IBSBattSOCWakeUp_Flg: type=boolean
    IF_ComM_IBSBattTemp_C: invalidation-policy{data-element=tec_ComM_IBSBattTemp_C, handle-invalid=DONT-INVALIDATE}
      data tec_ComM_IBSBattTemp_C: type=float32
    IF_ComM_IBSBattUDc_V: invalidation-policy{data-element=tec_ComM_IBSBattUDc_V, handle-invalid=DONT-INVALIDATE}
      data tec_ComM_IBSBattUDc_V: type=float32
    IF_ComM_IVIPrecReq_Flg: invalidation-policy{data-element=tec_ComM_IVIPrecReq_Flg, handle-invalid=DONT-INVALIDATE}
      data tec_ComM_IVIPrecReq_Flg: type=boolean
    IF_ComM_IVIPreheatReq_Flg: invalidation-policy{data-element=tec_ComM_IVIPreheatReq_Flg, handle-invalid=DONT-INVALIDATE}
      data tec_ComM_IVIPreheatReq_Flg: type=boolean
    IF_ComM_MCUWrkMod_Enum: invalidation-policy{data-element=tec_ComM_MCUWrkMod_Enum, handle-invalid=DONT-INVALIDATE}
      data tec_ComM_MCUWrkMod_Enum: type=uint8
    IF_ComM_OBCCCSts_Enum: invalidation-policy{data-element=tec_ComM_OBCCCSts_Enum, handle-invalid=DONT-INVALIDATE}
      data tec_ComM_OBCCCSts_Enum: type=uint8
    IF_ComM_OBCChrgSts_Enum: invalidation-policy{data-element=tec_ComM_OBCChrgSts_Enum, handle-invalid=DONT-INVALIDATE}
      data tec_ComM_OBCChrgSts_Enum: type=uint8
    IF_ComM_PEPSPwrMod_Enum: invalidation-policy{data-element=tec_ComM_PEPSPwrMod_Enum, handle-invalid=DONT-INVALIDATE}
      data tec_ComM_PEPSPwrMod_Enum: type=uint8
    IF_ComM_SGWAcReq_Flg: invalidation-policy{data-element=tec_ComM_SGWAcReq_Flg, handle-invalid=DONT-INVALIDATE}
      data tec_ComM_SGWAcReq_Flg: type=boolean
    IF_ComM_SGWWakeUpReq_Flg: invalidation-policy{data-element=tec_ComM_SGWWakeUpReq_Flg, handle-invalid=DONT-INVALIDATE}
      data tec_ComM_SGWWakeUpReq_Flg: type=boolean
    IF_ErrMgmt_OBCMesgLoss_Flg: invalidation-policy{data-element=tec_ErrMgmt_OBCMesgLoss_Flg, handle-invalid=DONT-INVALIDATE}
      data tec_ErrMgmt_OBCMesgLoss_Flg: type=boolean
    IF_IOAbs_KL15Fb_Flg: invalidation-policy{data-element=tec_IOAbs_KL15Fb_Flg, handle-invalid=DONT-INVALIDATE}
      data tec_IOAbs_KL15Fb_Flg: type=boolean
    IF_LvMgmt_EISSDiagDTC_8bit: invalidation-policy{data-element=tec_LvMgmt_EISSDiagDTC_8bit, handle-invalid=DONT-INVALIDATE}
      data tec_LvMgmt_EISSDiagDTC_8bit: type=uint8
    IF_LvMgmt_IBSBattDiagSts_Enum: invalidation-policy{data-element=tec_LvMgmt_IBSBattDiagSts_Enum, handle-invalid=DONT-INVALIDATE}
      data tec_LvMgmt_IBSBattDiagSts_Enum: type=uint8
    IF_LvMgmt_IBSBattReChrgReq_Flg: invalidation-policy{data-element=tec_LvMgmt_IBSBattReChrgReq_Flg, handle-invalid=DONT-INVALIDATE}
      data tec_LvMgmt_IBSBattReChrgReq_Flg: type=boolean
    IF_LvMgmt_KL15ActSts_Flg: invalidation-policy{data-element=tec_LvMgmt_KL15ActSts_Flg, handle-invalid=DONT-INVALIDATE}
      data tec_LvMgmt_KL15ActSts_Flg: type=boolean
    IF_LvMgmt_KL15CtrlReq_Flg: invalidation-policy{data-element=tec_LvMgmt_KL15CtrlReq_Flg, handle-invalid=DONT-INVALIDATE}
      data tec_LvMgmt_KL15CtrlReq_Flg: type=boolean
    IF_LvMgmt_LvBattMgmtDiagDTC_8bit: invalidation-policy{data-element=tec_LvMgmt_LvBattMgmtDiagDTC_8bit, handle-invalid=DONT-INVALIDATE}
      data tec_LvMgmt_LvBattMgmtDiagDTC_8bit: type=uint8
    IF_LvMgmt_LvPwrDwn_Flg: invalidation-policy{data-element=tec_LvMgmt_LvPwrDwn_Flg, handle-invalid=DONT-INVALIDATE}
      data tec_LvMgmt_LvPwrDwn_Flg: type=boolean
    IF_LvMgmt_SelfChkSts_Flg: invalidation-policy{data-element=tec_LvMgmt_SelfChkSts_Flg, handle-invalid=DONT-INVALIDATE}
      data tec_LvMgmt_SelfChkSts_Flg: type=boolean
    IF_LvMgmt_StayInRun_Flg: invalidation-policy{data-element=tec_LvMgmt_StayInRun_Flg, handle-invalid=DONT-INVALIDATE}
      data tec_LvMgmt_StayInRun_Flg: type=boolean
    IF_LvMgmt_WakeUpReq_Flg: invalidation-policy{data-element=tec_LvMgmt_WakeUpReq_Flg, handle-invalid=DONT-INVALIDATE}
      data tec_LvMgmt_WakeUpReq_Flg: type=boolean
    IF_LvMgmt_WakeUpSrc_Enum: invalidation-policy{data-element=tec_LvMgmt_WakeUpSrc_Enum, handle-invalid=DONT-INVALIDATE}
      data tec_LvMgmt_WakeUpSrc_Enum: type=uint8
    IF_ModMgmt_HvSts_Enum: invalidation-policy{data-element=tec_ModMgmt_HvSts_Enum, handle-invalid=DONT-INVALIDATE}
      data tec_ModMgmt_HvSts_Enum: type=uint8
    IF_ModMgmt_ReqSleep_Flg: invalidation-policy{data-element=tec_ModMgmt_ReqSleep_Flg, handle-invalid=DONT-INVALIDATE}
      data tec_ModMgmt_ReqSleep_Flg: type=boolean
